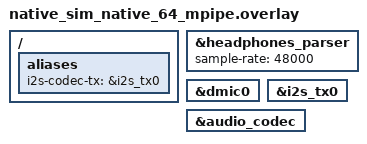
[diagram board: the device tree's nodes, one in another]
/*
 * Copyright 2026 NXP
 *
 * SPDX-License-Identifier: Apache-2.0
 */

/*
 * The pipelines of the media on native_sim, with its audio devices: the
 * emulated DMIC as the microphone, the emulated I2S behind the dummy codec as
 * the headphones, which runs at 48 kHz.
 */

#include "../pipelines.dtsi"

&headphones_parser {
	sample-rate = <48000>;
};

/ {
	aliases {
		i2s-codec-tx = &i2s_tx0;
	};
};

dmic_dev: &dmic0 {
	status = "okay";
};

&i2s_tx0 {
	status = "okay";
};

&audio_codec {
	status = "okay";
};
